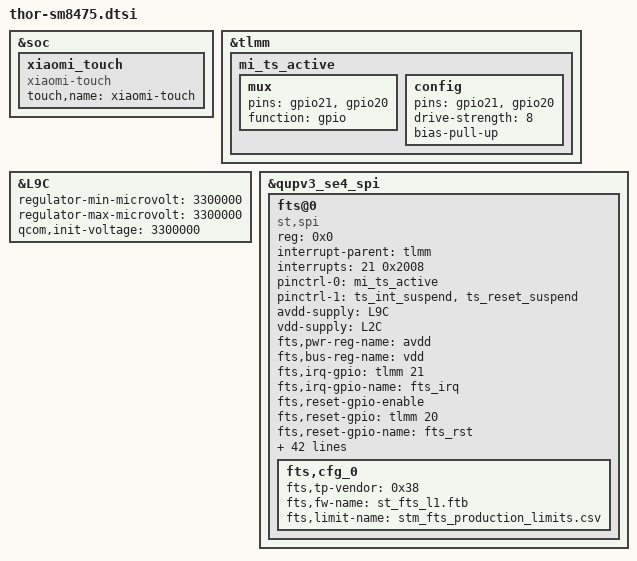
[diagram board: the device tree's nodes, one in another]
/*
   this file is for attribution only of thor
   And public attribution of xiaomi platforms
*/
#include "thor-8475-pinctrl.dtsi"
#include "xiaomi-sm8475-common.dtsi"

&soc {
	xiaomi_touch {
		compatible = "xiaomi-touch";
		status = "ok";
		touch,name = "xiaomi-touch";
	};
};

&tlmm {
	mi_ts_active: mi_ts_active {
		mux {
				pins = "gpio21", "gpio20";
				function = "gpio";
		};

		config {
				pins = "gpio21", "gpio20";
				drive-strength = <8>;
				bias-pull-up;
		};
	};
};

&L9C {
	regulator-min-microvolt = <3300000>;
	regulator-max-microvolt = <3300000>;
	qcom,init-voltage = <3300000>;
};

&qupv3_se4_spi {
	status = "ok";
	fts@0 {
		status = "ok";
		compatible = "st,spi";
		reg = <0x0>;
		interrupt-parent = <&tlmm>;
		interrupts = <21 0x2008>;
		pinctrl-names = "pmx_ts_active", "pmx_ts_suspend";
		pinctrl-0 = <&mi_ts_active>;
		pinctrl-1 = <&ts_int_suspend &ts_reset_suspend>;
		avdd-supply = <&L9C>;
		vdd-supply = <&L2C>;
		/*panel = <&dsi_k8_42_02_0a_dsc_cmd>;*/
		fts,pwr-reg-name = "avdd";
		fts,bus-reg-name = "vdd";
		fts,irq-gpio = <&tlmm 21 0x2008>;
		fts,irq-gpio-name = "fts_irq";
		fts,reset-gpio-enable;
		fts,reset-gpio = <&tlmm 20 0x00>;
		fts,reset-gpio-name = "fts_rst";
		fts,irq-flags = <0x2008>;
		fts,x-max = <14400>;
		fts,y-max = <32000>;
		fts,fod-lx = <5860>;
		fts,fod-ly = <23460>;
		fts,fod-x-size = <2680>;
		fts,fod-y-size = <2660>;
		fts,support-fod;
		spi-max-frequency = <12000000>;
		fts,support-super-resolution = <1>;
		fts,support-vsync-mode;
		fts,default-fw-name = "st_fts_l1.ftb";
		fts,thp-fw-name = "st_fts_l1_thp.ftb";
		fts,config-array-size = <1>;
		fts,touch-follow-performance-def = <3>;
		fts,touch-tap-sensitivity-def = <4>;
		fts,touch-aim-sensitivity-def = <3>;
		fts,touch-tap-stability-def = <3>;
		fts,cornerfilter-area-step1 = <150>;
		fts,cornerfilter-area-step2 = <280>;
		fts,cornerfilter-area-step3 = <400>;
		fts,touch-deadzone-filter-ver = <2 0 0 0 0 0 0 0
										2 1 0 0 0 0 0 0
										2 2 0 0 0 3199 0 0
										2 3 1439 0 1439 3199 0 0>;
		fts,touch-deadzone-filter-hor = <2 0 0 0 0 0 0 0
										2 1 0 0 0 0 0 0
										2 2 0 0 0 0 0 0
										2 3 0 0 0 0 0 0>;
		fts,touch-edgezone-filter-ver = <1 0 0 0 0 0 0 0
										1 1 0 0 0 0 0 0
										1 2 0 0 60 3199 0 0
										1 3 1379 0 1439 3199 0 0>;
		fts,touch-edgezone-filter-hor = <1 0 0 0 1439 60 0 0
										1 1 0 3139 1439 3199 0 0
										1 2 0 0 60 3199 0 0
										1 3 1379 0 1439 3199 0 0>;
		fts,touch-cornerzone-filter-ver = <0 0 0 0 0 0 0 0
										0 1 0 0 0 0 0 0
										0 2 0 2799 250 3199 0 0
										0 3 1189 2799 1439 3199 0 0>;
		fts,touch-cornerzone-filter-hor1 = <0 0 0 0 280 280 0 0
										0 1 0 0 0 0 0 0
										0 2 0 2919 280 3199 0 0
										0 3 0 0 0 0 0 0>;
		fts,touch-cornerzone-filter-hor2 = <0 0 0 0 0 0 0 0
										0 1 1159 0 1439 280 0 0
										0 2 0 0 0 0 0 0
										0 3 1159 2919 1439 3199 0 0>;
		fts,touch-follow-performance = <10 15 1
										8 15 1
										6 15 1
										4 15 1
										2 15 1>;
		fts,touch-tap-sensitivity = <160 150 140 120 100>;
		fts,touch-aim-sensitivity = <13 11 8 5 3>;
		fts,touch-tap-stability = <11 16 20 24 33>;
		fts,touch-expert-array = <6 15 1 120 8 20
								  2 15 1 120 5 20
								  4 15 1 120 3 20>;
		fts,cfg_0 {
			fts,tp-vendor = <0x38>;
			fts,fw-name = "st_fts_l1.ftb";
			fts,limit-name = "stm_fts_production_limits.csv";
		};
	};
};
